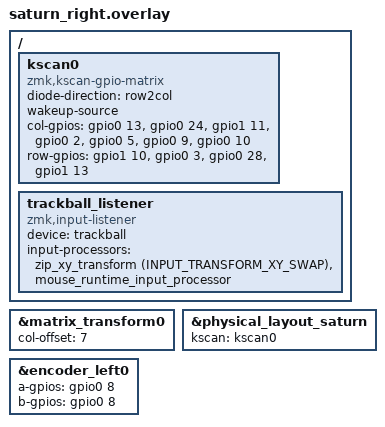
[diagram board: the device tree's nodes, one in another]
/*
 * Copyright (c) 2020 The ZMK Contributors
 *
 * SPDX-License-Identifier: MIT
 */

#include "saturn.dtsi"
#include "trackball.dtsi"
#include <dt-bindings/zmk/input_transform.h>
#include <input/processors.dtsi>
#include <input/processors/runtime-input-processor.dtsi>

// 4x7 matrix
// cols: P0.13 P0.24 P1.11 P0.02 P0.05 P0.09 P0.10 | rows: P1.10 P0.03 P0.28 P1.13
/ {
    kscan0: kscan0 {
        compatible = "zmk,kscan-gpio-matrix";
        diode-direction = "row2col";
        wakeup-source;

        col-gpios
            = <&gpio0 13 (GPIO_ACTIVE_HIGH | GPIO_PULL_DOWN)>
            , <&gpio0 24 (GPIO_ACTIVE_HIGH | GPIO_PULL_DOWN)>
            , <&gpio1 11 (GPIO_ACTIVE_HIGH | GPIO_PULL_DOWN)>
            , <&gpio0 2 (GPIO_ACTIVE_HIGH | GPIO_PULL_DOWN)>
            , <&gpio0 5 (GPIO_ACTIVE_HIGH | GPIO_PULL_DOWN)>
            , <&gpio0 9 (GPIO_ACTIVE_HIGH | GPIO_PULL_DOWN)>
            , <&gpio0 10 (GPIO_ACTIVE_HIGH | GPIO_PULL_DOWN)>
            ;

        row-gpios
            = <&gpio1 10 GPIO_ACTIVE_HIGH>
            , <&gpio0 3 GPIO_ACTIVE_HIGH>
            , <&gpio0 28 GPIO_ACTIVE_HIGH>
            , <&gpio1 13 GPIO_ACTIVE_HIGH>
            ;
    };
};

&matrix_transform0 {
    col-offset = <7>;
};

&physical_layout_saturn {
    kscan = <&kscan0>;
};

// Assigning dummy pins to the other part's encoder
// just to satisfy the devicetree requirements.
// No code will be compiled for this disabled encoder.
&encoder_left0 {
    a-gpios = <&gpio0 8 (GPIO_ACTIVE_HIGH | GPIO_PULL_UP)>;
    b-gpios = <&gpio0 8 (GPIO_ACTIVE_HIGH | GPIO_PULL_UP)>;
};

// Trackball input listener (the sensor lives on this half, which is central).
// XY_SWAP preserves the previous pmw3610 `swap-xy` orientation; adjust to your
// mounting if needed, or change it at runtime from DYA Studio.
/ {
    trackball_listener: trackball_listener {
        status = "okay";
        compatible = "zmk,input-listener";
        device = <&trackball>;
        input-processors = <&zip_xy_transform (INPUT_TRANSFORM_XY_SWAP)>,
                           <&mouse_runtime_input_processor>;
    };
};
